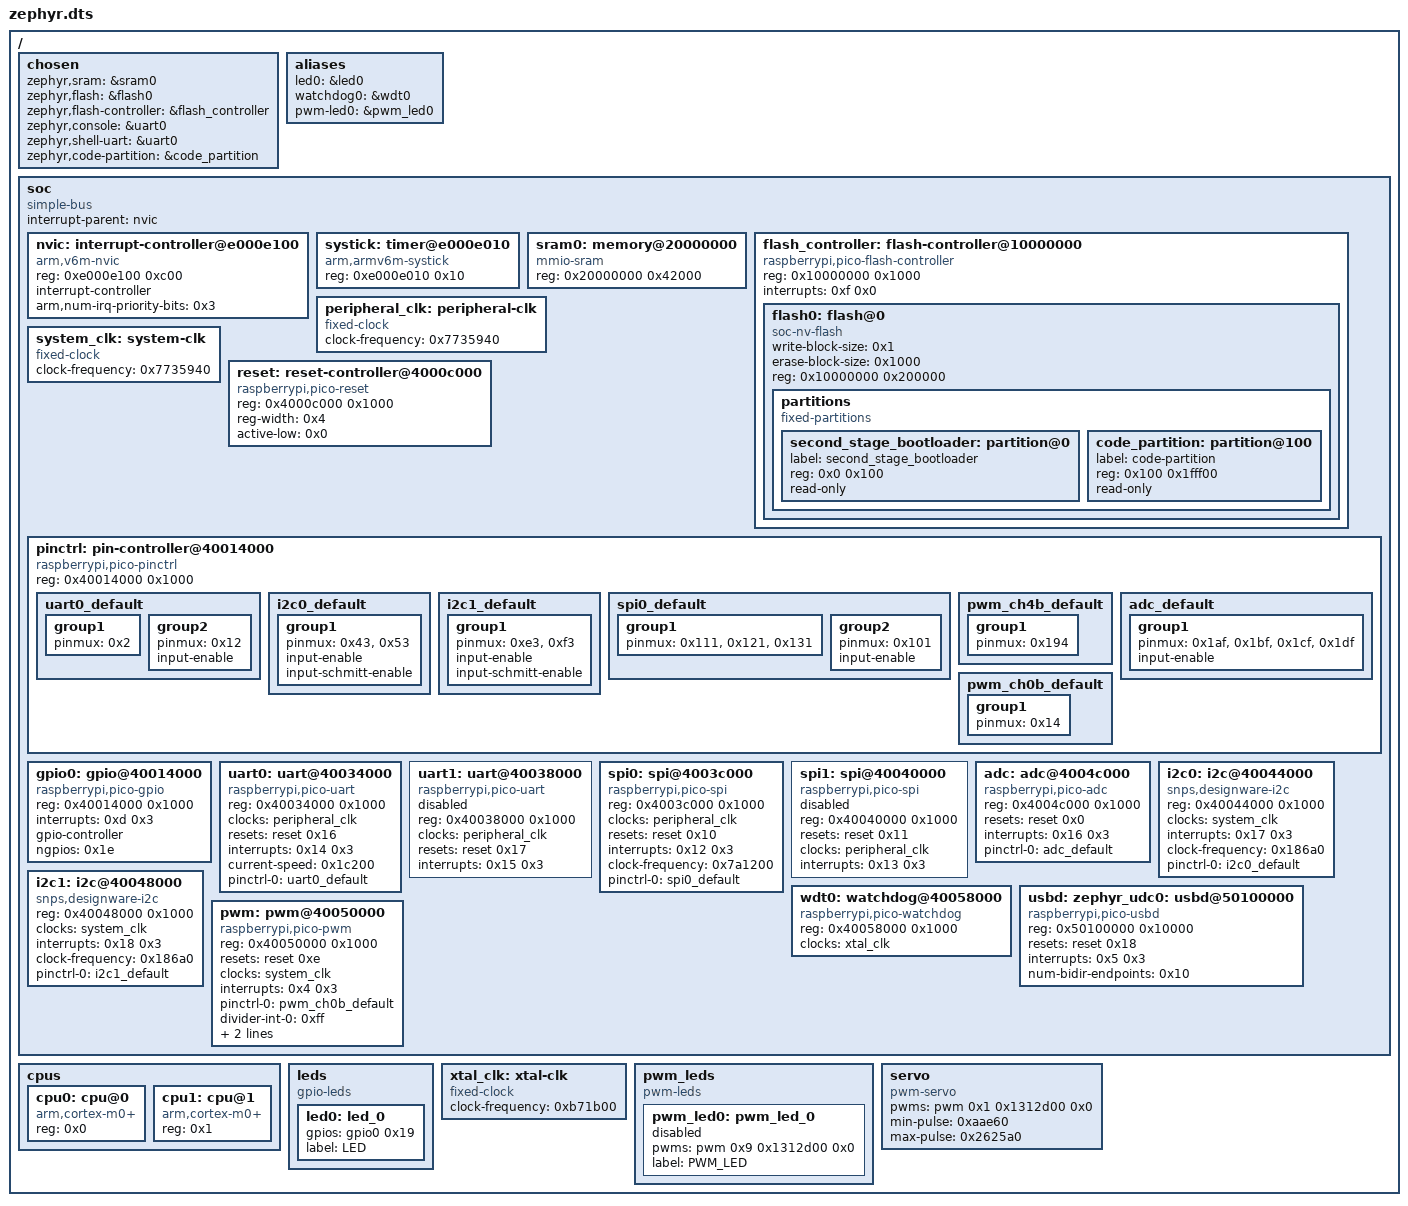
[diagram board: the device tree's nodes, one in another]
/dts-v1/;

/ {
	#address-cells = < 0x1 >;
	#size-cells = < 0x1 >;
	chosen {
		zephyr,sram = &sram0;
		zephyr,flash = &flash0;
		zephyr,flash-controller = &flash_controller;
		zephyr,console = &uart0;
		zephyr,shell-uart = &uart0;
		zephyr,code-partition = &code_partition;
	};
	aliases {
		led0 = &led0;
		watchdog0 = &wdt0;
		pwm-led0 = &pwm_led0;
	};
	soc {
		#address-cells = < 0x1 >;
		#size-cells = < 0x1 >;
		compatible = "simple-bus";
		interrupt-parent = < &nvic >;
		ranges;
		nvic: interrupt-controller@e000e100 {
			#address-cells = < 0x1 >;
			compatible = "arm,v6m-nvic";
			reg = < 0xe000e100 0xc00 >;
			interrupt-controller;
			#interrupt-cells = < 0x2 >;
			arm,num-irq-priority-bits = < 0x3 >;
			phandle = < 0x1 >;
		};
		systick: timer@e000e010 {
			compatible = "arm,armv6m-systick";
			reg = < 0xe000e010 0x10 >;
		};
		sram0: memory@20000000 {
			compatible = "mmio-sram";
			reg = < 0x20000000 0x42000 >;
		};
		flash_controller: flash-controller@10000000 {
			compatible = "raspberrypi,pico-flash-controller";
			reg = < 0x10000000 0x1000 >;
			interrupts = < 0xf 0x0 >;
			#address-cells = < 0x1 >;
			#size-cells = < 0x1 >;
			flash0: flash@0 {
				compatible = "soc-nv-flash";
				write-block-size = < 0x1 >;
				erase-block-size = < 0x1000 >;
				reg = < 0x10000000 0x200000 >;
				partitions {
					compatible = "fixed-partitions";
					#address-cells = < 0x1 >;
					#size-cells = < 0x1 >;
					second_stage_bootloader: partition@0 {
						label = "second_stage_bootloader";
						reg = < 0x0 0x100 >;
						read-only;
					};
					code_partition: partition@100 {
						label = "code-partition";
						reg = < 0x100 0x1fff00 >;
						read-only;
					};
				};
			};
		};
		peripheral_clk: peripheral-clk {
			compatible = "fixed-clock";
			clock-frequency = < 0x7735940 >;
			#clock-cells = < 0x0 >;
			phandle = < 0x2 >;
		};
		system_clk: system-clk {
			compatible = "fixed-clock";
			clock-frequency = < 0x7735940 >;
			#clock-cells = < 0x0 >;
			phandle = < 0x7 >;
		};
		reset: reset-controller@4000c000 {
			compatible = "raspberrypi,pico-reset";
			reg = < 0x4000c000 0x1000 >;
			reg-width = < 0x4 >;
			active-low = < 0x0 >;
			#reset-cells = < 0x1 >;
			phandle = < 0x3 >;
		};
		pinctrl: pin-controller@40014000 {
			compatible = "raspberrypi,pico-pinctrl";
			reg = < 0x40014000 0x1000 >;
			status = "okay";
			uart0_default: uart0_default {
				phandle = < 0x4 >;
				group1 {
					pinmux = < 0x2 >;
				};
				group2 {
					pinmux = < 0x12 >;
					input-enable;
				};
			};
			i2c0_default: i2c0_default {
				phandle = < 0x8 >;
				group1 {
					pinmux = < 0x43 >, < 0x53 >;
					input-enable;
					input-schmitt-enable;
				};
			};
			i2c1_default: i2c1_default {
				phandle = < 0x9 >;
				group1 {
					pinmux = < 0xe3 >, < 0xf3 >;
					input-enable;
					input-schmitt-enable;
				};
			};
			spi0_default: spi0_default {
				phandle = < 0x5 >;
				group1 {
					pinmux = < 0x111 >, < 0x121 >, < 0x131 >;
				};
				group2 {
					pinmux = < 0x101 >;
					input-enable;
				};
			};
			pwm_ch4b_default: pwm_ch4b_default {
				group1 {
					pinmux = < 0x194 >;
				};
			};
			adc_default: adc_default {
				phandle = < 0x6 >;
				group1 {
					pinmux = < 0x1af >, < 0x1bf >, < 0x1cf >, < 0x1df >;
					input-enable;
				};
			};
			pwm_ch0b_default: pwm_ch0b_default {
				phandle = < 0xb >;
				group1 {
					pinmux = < 0x14 >;
				};
			};
		};
		gpio0: gpio@40014000 {
			compatible = "raspberrypi,pico-gpio";
			reg = < 0x40014000 0x1000 >;
			interrupts = < 0xd 0x3 >;
			gpio-controller;
			#gpio-cells = < 0x2 >;
			status = "okay";
			ngpios = < 0x1e >;
			phandle = < 0xc >;
		};
		uart0: uart@40034000 {
			compatible = "raspberrypi,pico-uart";
			reg = < 0x40034000 0x1000 >;
			clocks = < &peripheral_clk >;
			resets = < &reset 0x16 >;
			interrupts = < 0x14 0x3 >;
			interrupt-names = "uart0";
			status = "okay";
			current-speed = < 0x1c200 >;
			pinctrl-0 = < &uart0_default >;
			pinctrl-names = "default";
		};
		uart1: uart@40038000 {
			compatible = "raspberrypi,pico-uart";
			reg = < 0x40038000 0x1000 >;
			clocks = < &peripheral_clk >;
			resets = < &reset 0x17 >;
			interrupts = < 0x15 0x3 >;
			interrupt-names = "uart1";
			status = "disabled";
		};
		spi0: spi@4003c000 {
			compatible = "raspberrypi,pico-spi", "arm,pl022";
			#address-cells = < 0x1 >;
			#size-cells = < 0x0 >;
			reg = < 0x4003c000 0x1000 >;
			clocks = < &peripheral_clk >;
			resets = < &reset 0x10 >;
			interrupts = < 0x12 0x3 >;
			interrupt-names = "spi0";
			status = "okay";
			clock-frequency = < 0x7a1200 >;
			pinctrl-0 = < &spi0_default >;
			pinctrl-names = "default";
		};
		spi1: spi@40040000 {
			compatible = "raspberrypi,pico-spi", "arm,pl022";
			#address-cells = < 0x1 >;
			#size-cells = < 0x0 >;
			reg = < 0x40040000 0x1000 >;
			resets = < &reset 0x11 >;
			clocks = < &peripheral_clk >;
			interrupts = < 0x13 0x3 >;
			interrupt-names = "spi1";
			status = "disabled";
		};
		adc: adc@4004c000 {
			compatible = "raspberrypi,pico-adc";
			reg = < 0x4004c000 0x1000 >;
			resets = < &reset 0x0 >;
			interrupts = < 0x16 0x3 >;
			interrupt-names = "adc0";
			status = "okay";
			#io-channel-cells = < 0x1 >;
			pinctrl-0 = < &adc_default >;
			pinctrl-names = "default";
		};
		i2c0: i2c@40044000 {
			compatible = "snps,designware-i2c";
			#address-cells = < 0x1 >;
			#size-cells = < 0x0 >;
			reg = < 0x40044000 0x1000 >;
			clocks = < &system_clk >;
			interrupts = < 0x17 0x3 >;
			interrupt-names = "i2c0";
			status = "okay";
			clock-frequency = < 0x186a0 >;
			pinctrl-0 = < &i2c0_default >;
			pinctrl-names = "default";
		};
		i2c1: i2c@40048000 {
			compatible = "snps,designware-i2c";
			#address-cells = < 0x1 >;
			#size-cells = < 0x0 >;
			reg = < 0x40048000 0x1000 >;
			clocks = < &system_clk >;
			interrupts = < 0x18 0x3 >;
			interrupt-names = "i2c1";
			status = "okay";
			clock-frequency = < 0x186a0 >;
			pinctrl-0 = < &i2c1_default >;
			pinctrl-names = "default";
		};
		wdt0: watchdog@40058000 {
			compatible = "raspberrypi,pico-watchdog";
			reg = < 0x40058000 0x1000 >;
			clocks = < &xtal_clk >;
			status = "okay";
		};
		usbd: zephyr_udc0: usbd@50100000 {
			compatible = "raspberrypi,pico-usbd";
			reg = < 0x50100000 0x10000 >;
			resets = < &reset 0x18 >;
			interrupts = < 0x5 0x3 >;
			interrupt-names = "usbctrl";
			num-bidir-endpoints = < 0x10 >;
			status = "okay";
		};
		pwm: pwm@40050000 {
			compatible = "raspberrypi,pico-pwm";
			reg = < 0x40050000 0x1000 >;
			resets = < &reset 0xe >;
			clocks = < &system_clk >;
			interrupts = < 0x4 0x3 >;
			interrupt-names = "PWM_IRQ_WRAP";
			status = "okay";
			#pwm-cells = < 0x3 >;
			pinctrl-0 = < &pwm_ch0b_default >;
			pinctrl-names = "default";
			divider-int-0 = < 0xff >;
			divider-frac-4 = < 0xff >;
			divider-int-4 = < 0xff >;
			phandle = < 0xd >;
		};
	};
	cpus {
		#address-cells = < 0x1 >;
		#size-cells = < 0x0 >;
		cpu0: cpu@0 {
			compatible = "arm,cortex-m0+";
			reg = < 0x0 >;
		};
		cpu1: cpu@1 {
			compatible = "arm,cortex-m0+";
			reg = < 0x1 >;
		};
	};
	leds {
		compatible = "gpio-leds";
		led0: led_0 {
			gpios = < &gpio0 0x19 0x0 >;
			label = "LED";
		};
	};
	xtal_clk: xtal-clk {
		compatible = "fixed-clock";
		clock-frequency = < 0xb71b00 >;
		#clock-cells = < 0x0 >;
		phandle = < 0xa >;
	};
	pwm_leds {
		compatible = "pwm-leds";
		pwm_led0: pwm_led_0 {
			status = "disabled";
			pwms = < &pwm 0x9 0x1312d00 0x0 >;
			label = "PWM_LED";
		};
	};
	servo: servo {
		compatible = "pwm-servo";
		pwms = < &pwm 0x1 0x1312d00 0x0 >;
		min-pulse = < 0xaae60 >;
		max-pulse = < 0x2625a0 >;
	};
};
